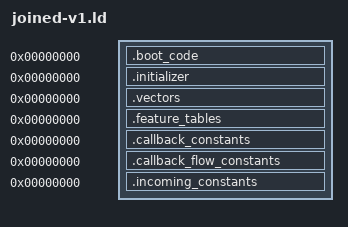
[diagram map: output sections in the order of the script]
OUTPUT_ARCH(riscv)
SECTIONS
{
 .boot_code 0 : SUBALIGN(2) { *(.boot_code)
  *(.text.tsl9_main_services_provider_11442)
  *(.text.tsl9_registered_callbacks_block_11452)
  *(.text.tsl9_registered_callbacks_block_11458)
  *(.text.tsl9_registered_callbacks_block_11464)
  *(.text.tsl9_registered_callbacks_block_1146e)
  *(.text.tsl9_registered_callbacks_block_11474)
  *(.text.tsl9_registered_callbacks_block_1147a)
  *(.text.tsl9_registered_callbacks_block_11480)
  *(.text.tsl9_registered_callbacks_block_11486)
  *(.text.tsl9_registered_callbacks_block_11494)
  *(.text.tsl9_registered_callbacks_block_1149a)
  *(.text.tsl9_registered_callbacks_block_114a0)
  *(.text.tsl9_registered_callbacks_block_114b0)
  *(.text.tsl9_registered_callbacks_block_114be)
  *(.text.tsl9_registered_callbacks_block_114c4)
  *(.text.tsl9_registered_callbacks_block_114cc)
  *(.text.tsl9_main_services_provider_119c8)
  *(.text.tsl9_registered_callbacks_block_119ee)
  *(.text.tsl9_registered_callbacks_block_119f6)
  *(.text.tsl9_registered_callbacks_block_119fc)
  *(.text.tsl9_registered_callbacks_block_11a08)
  *(.text.tsl9_registered_callbacks_block_11a20)
  *(.text.tsl9_registered_callbacks_block_11a2c)
  *(.text.tsl9_registered_callbacks_block_11a38)
  *(.text.tsl9_registered_callbacks_block_11a40)
  *(.text.tsl9_registered_callbacks_block_11a58)
  *(.text.tsl9_registered_callbacks_block_11a6e)
  *(.text.tsl9_registered_callbacks_block_11a72)
  *(.text.tsl9_registered_callbacks_block_11a7a)
  *(.text.tsl9_registered_callbacks_block_11a88)
  *(.text.tsl9_registered_callbacks_block_11a92)
  *(.text.tsl9_registered_callbacks_block_11a96)
  *(.text.tsl9_registered_callbacks_block_11aa8)
  *(.text.tsl9_registered_callbacks_block_11aac)
  *(.text.tsl9_registered_callbacks_block_11abe)
  *(.text.tsl9_registered_callbacks_block_11ac2)
  *(.text.tsl9_registered_callbacks_block_11ac8)
  *(.text.tsl9_registered_callbacks_block_11ad4)
  *(.text.tsl9_registered_callbacks_block_11ae0)
  *(.text.tsl9_registered_callbacks_block_11aec)
  *(.text.tsl9_registered_callbacks_block_11af8)
  *(.text.tsl9_registered_callbacks_block_11b00)
  *(.text.tsl9_registered_callbacks_block_11b0a)
  *(.text.tsl9_registered_callbacks_block_11b14)
  *(.text.tsl9_registered_callbacks_block_11b3e)
  *(.text.tsl9_registered_callbacks_block_11b48)
  *(.text.tsl9_registered_callbacks_block_11b6e)
  *(.text.tsl9_registered_callbacks_block_11b84)
  *(.text.tsl9_registered_callbacks_block_11b88)
  *(.text.tsl9_registered_callbacks_block_11b90)
  *(.text.tsl9_registered_callbacks_block_11b98)
  *(.text.tsl9_registered_callbacks_block_11ba0)
  *(.text.tsl9_registered_callbacks_block_11ba2)
  *(.text.tsl9_registered_callbacks_block_11baa)
  *(.text.tsl9_registered_callbacks_block_11bae)
  *(.text.tsl9_registered_callbacks_block_11bb2)
  *(.text.tsl9_registered_callbacks_block_11bb6)
  *(.text.tsl9_registered_callbacks_block_11bc0)
  *(.text.tsl9_registered_callbacks_block_11bc2)
  *(.text.tsl9_registered_callbacks_block_11bca)
  *(.text.tsl9_registered_callbacks_block_11bce)
  *(.text.tsl9_registered_callbacks_block_11bd8)
  *(.text.tsl9_registered_callbacks_block_11bdc)
  *(.text.tsl9_registered_callbacks_block_11be4)
  *(.text.tsl9_registered_callbacks_block_11be8)
  *(.text.tsl9_registered_callbacks_block_11bf0)
  *(.text.tsl9_registered_callbacks_block_11bf2)
  *(.text.tsl9_registered_callbacks_block_11bfa)
  *(.text.tsl9_registered_callbacks_block_11bfe)
  *(.text.tsl9_registered_callbacks_block_11c10)
  *(.text.tsl9_registered_callbacks_block_11c12)
  *(.text.tsl9_registered_callbacks_block_11c18)
  *(.text.tsl9_registered_callbacks_block_11c24)
  *(.text.tsl9_registered_callbacks_block_11c2e)
  *(.text.tsl9_registered_callbacks_block_11c3a)
  *(.text.tsl9_registered_callbacks_block_11c44)
  *(.text.tsl9_registered_callbacks_block_11c56)
  *(.text.tsl9_registered_callbacks_block_11c58)
  *(.text.tsl9_registered_callbacks_block_11c5e)
  *(.text.tsl9_registered_callbacks_block_11c64)
  *(.text.tsl9_registered_callbacks_block_11c78)
  *(.text.tsl9_registered_callbacks_block_11cb0)
  *(.text.tsl9_registered_callbacks_block_11cc6)
  *(.text.tsl9_registered_callbacks_block_11cc8)
  *(.text.tsl9_registered_callbacks_block_11cda)
  *(.text.tsl9_registered_callbacks_block_11cdc)
  *(.text.tsl9_registered_callbacks_block_11ce2)
  *(.text.tsl9_registered_callbacks_block_11cea)
  *(.text.tsl9_registered_callbacks_block_11cf2)
  *(.text.tsl9_registered_callbacks_block_11cfa)
  *(.text.tsl9_registered_callbacks_block_11d02)
  *(.text.tsl9_registered_callbacks_block_11d0a)
  *(.text.tsl9_registered_callbacks_block_11d12)
  *(.text.tsl9_registered_callbacks_block_11d1e)
  *(.text.tsl9_registered_callbacks_block_11d26)
  *(.text.tsl9_registered_callbacks_block_11d38)
  *(.text.tsl9_registered_callbacks_block_11d3a)
  *(.text.tsl9_registered_callbacks_block_11d4c)
  *(.text.tsl9_registered_callbacks_block_11d4e)
  *(.text.tsl9_registered_callbacks_block_11d60)
  *(.text.tsl9_registered_callbacks_block_11d62)
  *(.text.tsl9_registered_callbacks_block_11d78)
  *(.text.tsl9_registered_callbacks_block_11d7c)
  *(.text.tsl9_registered_callbacks_block_11d82)
  *(.text.tsl9_registered_callbacks_block_11d8a)
  *(.text.tsl9_registered_callbacks_block_11d92)
  *(.text.tsl9_registered_callbacks_block_11d9c)
  *(.text.tsl9_registered_callbacks_block_11da8)
  *(.text.tsl9_registered_callbacks_block_11db0)
  *(.text.tsl9_registered_callbacks_block_11dbc)
  *(.text.tsl9_registered_callbacks_block_11dc6)
  *(.text.tsl9_registered_callbacks_block_11dce)
  *(.text.tsl9_registered_callbacks_block_11dd4)
  *(.text.tsl9_registered_callbacks_block_11ddc)
  *(.text.tsl9_registered_callbacks_block_11de4)
  *(.text.tsl9_registered_callbacks_block_11dec)
  *(.text.tsl9_registered_callbacks_block_11df4)
  *(.text.tsl9_registered_callbacks_block_11dfc)
  *(.text.tsl9_registered_callbacks_block_11e0c)
  *(.text.tsl9_registered_callbacks_block_11e12)
  *(.text.tsl9_registered_callbacks_block_11e16)
  *(.text.tsl9_registered_callbacks_block_11e1c)
  *(.text.tsl9_registered_callbacks_block_11e24)
  *(.text.tsl9_registered_callbacks_block_11e3e)
  *(.text.tsl9_registered_callbacks_block_11e46)
  *(.text.tsl9_registered_callbacks_block_11e50)
  *(.text.tsl9_registered_callbacks_block_11e5c)
  *(.text.tsl9_registered_callbacks_block_11e66)
  *(.text.tsl9_registered_callbacks_block_11e78)
  *(.text.tsl9_registered_callbacks_block_11e80)
  *(.text.tsl9_registered_callbacks_block_11e8a)
  *(.text.tsl9_registered_callbacks_block_11e9c)
  *(.text.tsl9_registered_callbacks_block_11ea4)
  *(.text.tsl9_registered_callbacks_block_11eae)
  *(.text.tsl9_registered_callbacks_block_11ec0)
  *(.text.tsl9_registered_callbacks_block_11ec6)
  *(.text.tsl9_registered_callbacks_block_11ece)
  *(.text.tsl9_registered_callbacks_block_11ed2)
  *(.text.tsl9_registered_callbacks_block_11ee4)
  *(.text.tsl9_registered_callbacks_block_11ef6)
  *(.text.tsl9_registered_callbacks_block_11ef8)
  *(.text.tsl9_registered_callbacks_block_11efe)
  *(.text.tsl9_registered_callbacks_block_11f08)
  *(.text.tsl9_registered_callbacks_block_11f18)
  *(.text.tsl9_registered_callbacks_block_11f1e)
  *(.text.tsl9_registered_callbacks_block_11f2e)
  *(.text.tsl9_registered_callbacks_block_11f32)
  *(.text.tsl9_registered_callbacks_block_11f3a)
  *(.text.tsl9_registered_callbacks_block_11f40)
  *(.text.tsl9_registered_callbacks_block_11f48)
  *(.text.tsl9_registered_callbacks_block_11f4e)
  *(.text.tsl9_registered_callbacks_block_11f50)
  *(.text.tsl9_registered_callbacks_block_11f58)
  *(.text.tsl9_registered_callbacks_block_11f5e)
  *(.text.tsl9_registered_callbacks_block_11f6a)
  *(.text.tsl9_registered_callbacks_block_11f72)
  *(.text.tsl9_registered_callbacks_block_11f7a)
  *(.text.tsl9_registered_callbacks_block_11f7e)
  *(.text.tsl9_registered_callbacks_block_11f8a)
  *(.text.tsl9_registered_callbacks_block_11f92)
  *(.text.tsl9_registered_callbacks_block_11f98)
  *(.text.tsl9_registered_callbacks_block_11fa0)
  *(.text.tsl9_registered_callbacks_block_11faa)
  *(.text.tsl9_registered_callbacks_block_11fb8)
  *(.text.tsl9_registered_callbacks_block_11fbc)
  *(.text.tsl9_registered_callbacks_block_11fc0)
  *(.text.tsl9_registered_callbacks_block_11fd8)
  *(.text.tsl9_registered_callbacks_block_11fea)
  *(.text.tsl9_registered_callbacks_block_11fec)
  *(.text.tsl9_registered_callbacks_block_11ff2)
  *(.text.tsl9_registered_callbacks_block_11ffe)
  *(.text.tsl9_registered_callbacks_block_12006)
  *(.text.tsl9_registered_callbacks_block_1200e)
  *(.text.tsl9_registered_callbacks_block_12020)
  *(.text.tsl9_registered_callbacks_block_12026)
  *(.text.tsl9_registered_callbacks_block_1202e)
  *(.text.tsl9_registered_callbacks_block_12046)
  *(.text.tsl9_registered_callbacks_block_12060)
  *(.text.tsl9_registered_callbacks_block_12062)
  *(.text.tsl9_registered_callbacks_block_1207a)
  *(.text.tsl9_registered_callbacks_block_1209c)
  *(.text.tsl9_registered_callbacks_block_120a8)
  *(.text.tsl9_registered_callbacks_block_120aa)
  *(.text.tsl9_registered_callbacks_block_120bc)
  *(.text.tsl9_registered_callbacks_block_120be)
  *(.text.tsl9_registered_callbacks_block_120c4)
  *(.text.tsl9_registered_callbacks_block_120cc)
  *(.text.tsl9_registered_callbacks_block_120d4)
  *(.text.tsl9_registered_callbacks_block_120dc)
  *(.text.tsl9_registered_callbacks_block_120e4)
  *(.text.tsl9_registered_callbacks_block_120f0)
  *(.text.tsl9_registered_callbacks_block_120f6)
  *(.text.tsl9_registered_callbacks_block_12114)
  *(.text.tsl9_registered_callbacks_block_12126)
  *(.text.tsl9_registered_callbacks_block_12128)
  *(.text.tsl9_registered_callbacks_block_1213a)
  *(.text.tsl9_registered_callbacks_block_1213e)
  *(.text.tsl9_registered_callbacks_block_12144)
  *(.text.tsl9_registered_callbacks_block_1214c)
  *(.text.tsl9_registered_callbacks_block_12154)
  *(.text.tsl9_registered_callbacks_block_1215c)
  *(.text.tsl9_registered_callbacks_block_12164)
  *(.text.tsl9_registered_callbacks_block_1216c)
  *(.text.tsl9_registered_callbacks_block_12186)
  *(.text.tsl9_registered_callbacks_block_1218c)
  *(.text.tsl9_registered_callbacks_block_12198)
  *(.text.tsl9_registered_callbacks_block_121a8)
  *(.text.tsl9_registered_callbacks_block_121ba)
  *(.text.tsl9_registered_callbacks_block_121bc)
  *(.text.tsl9_registered_callbacks_block_121c6)
  *(.text.tsl9_registered_callbacks_block_121d4)
  *(.text.tsl9_registered_callbacks_block_121e2)
  *(.text.tsl9_registered_callbacks_block_12208)
  *(.text.tsl9_registered_callbacks_block_1220c)
  *(.text.tsl9_registered_callbacks_block_1222a)
  *(.text.tsl9_registered_callbacks_block_1222e)
  *(.text.tsl9_registered_callbacks_block_12232)
  *(.text.tsl9_registered_callbacks_block_12236)
  *(.text.tsl9_registered_callbacks_block_12240)
  *(.text.tsl9_registered_callbacks_block_12244)
  *(.text.tsl9_registered_callbacks_block_1224c)
  *(.text.tsl9_registered_callbacks_block_12262)
  *(.text.tsl9_registered_callbacks_block_1226a)
  *(.text.tsl9_registered_callbacks_block_1226e)
  *(.text.tsl9_registered_callbacks_block_12276)
  *(.text.tsl9_registered_callbacks_block_1227e)
  *(.text.tsl9_registered_callbacks_block_12288)
  *(.text.tsl9_registered_callbacks_block_12290)
  *(.text.tsl9_registered_callbacks_block_12292)
  *(.text.tsl9_registered_callbacks_block_12298)
  *(.text.tsl9_registered_callbacks_block_122aa)
  *(.text.tsl9_registered_callbacks_block_122ac)
  *(.text.tsl9_registered_callbacks_block_122b8)
  *(.text.tsl9_registered_callbacks_block_122be)
  *(.text.tsl9_registered_callbacks_block_122c6)
  *(.text.tsl9_registered_callbacks_block_122c8)
  *(.text.tsl9_registered_callbacks_block_122ce)
  *(.text.tsl9_registered_callbacks_block_122d8)
  *(.text.tsl9_registered_callbacks_block_122de)
  *(.text.tsl9_registered_callbacks_block_122e4)
  *(.text.tsl9_registered_callbacks_block_122ee)
  *(.text.tsl9_registered_callbacks_block_1230c)
  *(.text.tsl9_registered_callbacks_block_12312)
  *(.text.tsl9_registered_callbacks_block_12318)
  *(.text.tsl9_registered_callbacks_block_12326)
  *(.text.tsl9_registered_callbacks_block_12332)
  *(.text.tsl9_registered_callbacks_block_12336)
  *(.text.tsl9_registered_callbacks_block_1233c)
  *(.text.tsl9_registered_callbacks_block_12350)
  *(.text.tsl9_registered_callbacks_block_1235c)
  *(.text.tsl9_registered_callbacks_block_12362)
  *(.text.tsl9_registered_callbacks_block_1236a)
  *(.text.tsl9_registered_callbacks_block_12384)
  *(.text.tsl9_registered_callbacks_block_1238a)
  *(.text.tsl9_registered_callbacks_block_123a8)
  *(.text.tsl9_registered_callbacks_block_123aa)
  *(.text.tsl9_registered_callbacks_block_123c0)
  *(.text.tsl9_registered_callbacks_block_123c4)
  *(.text.tsl9_registered_callbacks_block_123ca)
  *(.text.tsl9_registered_callbacks_block_123d0)
  *(.text.tsl9_registered_callbacks_block_123d6)
  *(.text.tsl9_registered_callbacks_block_123dc)
  *(.text.tsl9_registered_callbacks_block_123e2)
  *(.text.tsl9_registered_callbacks_block_123e8)
  *(.text.tsl9_registered_callbacks_block_123ee)
  *(.text.tsl9_registered_callbacks_block_123f4)
  *(.text.tsl9_registered_callbacks_block_123fe)
  *(.text.tsl9_registered_callbacks_block_12402)
  *(.text.tsl9_registered_callbacks_block_12406)
  *(.text.tsl9_registered_callbacks_block_1240c)
  *(.text.tsl9_registered_callbacks_block_1241e)
  *(.text.tsl9_registered_callbacks_block_12428)
  *(.text.tsl9_registered_callbacks_block_1242c)
  *(.text.tsl9_registered_callbacks_block_1244a)
  *(.text.tsl9_registered_callbacks_block_1244e)
  *(.text.tsl9_registered_callbacks_block_12458)
  *(.text.tsl9_registered_callbacks_block_1245c)
  *(.text.tsl9_registered_callbacks_block_12462)
  *(.text.tsl9_registered_callbacks_block_12468)
  *(.text.tsl9_registered_callbacks_block_12480)
  *(.text.tsl9_registered_callbacks_block_12488)
  *(.text.tsl9_registered_callbacks_block_12492)
  *(.text.tsl9_registered_callbacks_block_1249a)
  *(.text.tsl9_registered_callbacks_block_1249c)
  *(.text.tsl9_registered_callbacks_block_124a2)
  *(.text.tsl9_registered_callbacks_block_124a8)
  *(.text.tsl9_registered_callbacks_block_124ae)
  *(.text.tsl9_registered_callbacks_block_124b4)
  *(.text.tsl9_registered_callbacks_block_124bc)
  *(.text.tsl9_registered_callbacks_block_124be)
  *(.text.tsl9_registered_callbacks_block_124c6)
  *(.text.tsl9_registered_callbacks_block_124ce)
  *(.text.tsl9_registered_callbacks_block_124da)
  *(.text.tsl9_registered_callbacks_block_124e0)
  *(.text.tsl9_registered_callbacks_block_124e4)
  *(.text.tsl9_registered_callbacks_block_124f6)
  *(.text.tsl9_registered_callbacks_block_124fe)
  *(.text.tsl9_registered_callbacks_block_12504)
  *(.text.tsl9_main_services_provider_16f00)
  *(.text.tsl9_registered_callbacks_block_16f10)
  *(.text.tsl9_registered_callbacks_block_16f20)
  *(.text.tsl9_registered_callbacks_block_16f24)
  *(.text.tsl9_registered_callbacks_block_16f28)
  *(.text.tsl9_registered_callbacks_block_16f32)
  *(.text.tsl9_registered_callbacks_block_16f3c)
  *(.text.tsl9_registered_callbacks_block_16f3e)
  *(.text.tsl9_registered_callbacks_block_16f44)
  *(.text.tsl9_registered_callbacks_block_16f46)
  *(.text.tsl9_registered_callbacks_block_16f4c)
  *(.text.tsl9_registered_callbacks_block_16f5c)
  *(.text.tsl9_registered_callbacks_block_16f60)
  *(.text.tsl9_registered_callbacks_block_16f66)
  *(.text.tsl9_registered_callbacks_block_16f70)
  *(.text.tsl9_registered_callbacks_block_16f72)
  *(.text.tsl9_registered_callbacks_block_16f78)
  *(.text.tsl9_registered_callbacks_block_16f7a)
  *(.text.tsl9_registered_callbacks_block_16f84)
  *(.text.tsl9_registered_callbacks_block_16f8a)
  *(.text.tsl9_registered_callbacks_block_16f8c)
  *(.text.tsl9_registered_callbacks_block_16f92)
  *(.text.tsl9_registered_callbacks_block_16f94)
  *(.text.tsl9_registered_callbacks_block_16f98)
  *(.text.tsl9_registered_callbacks_block_16f9e)
  *(.text.tsl9_registered_callbacks_block_16fa4)
  *(.text.tsl9_registered_callbacks_block_16fb4)
 }
 .initializer 0 : SUBALIGN(4) { *(.initializer) }
 .vectors 0 : SUBALIGN(4) { *(.vectors) }
 .feature_tables 0 : SUBALIGN(4) { *(.feature_tables) }
 .callback_constants 0 : SUBALIGN(4) { *(.callback_constants) }
 .callback_flow_constants 0 : SUBALIGN(4) { *(.callback_flow_constants) }
 .incoming_constants 0 : SUBALIGN(4) { *(.incoming_constants) }
 /DISCARD/ : { *(.comment) *(.riscv.attributes) *(.llvm_addrsig) }
}
